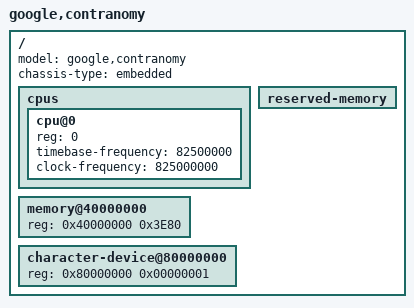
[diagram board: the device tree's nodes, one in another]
// SPDX-FileCopyrightText: 2022 Google LLC
//
// SPDX-License-Identifier: Apache-2.0

/dts-v1/;

/ {

  #address-cells = <1>;
  #size-cells = <1>;

  model = "google,contranomy";

  compatible;

  chassis-type = "embedded";

  cpus {
    #address-cells = <1>;
    #size-cells = <0>;

    cpu@0 {
      device_type = "cpu";
      reg = <0>;

      timebase-frequency = <82500000>; // 8.25 MHz
      clock-frequency = <825000000>; // 825 MHz

      status = "okay";
    };
  };

  memory@40000000 {
    device_type = "memory";
    reg = <0x40000000 0x3E80>;
  };

  reserved-memory {
    #address-cells = <1>;
    #size-cells = <1>;
    ranges;
  };

  character-device@80000000 {
    #address-cells = <1>;
    #size-cells = <1>;
    reg = <0x80000000 0x00000001>;
  };

};
